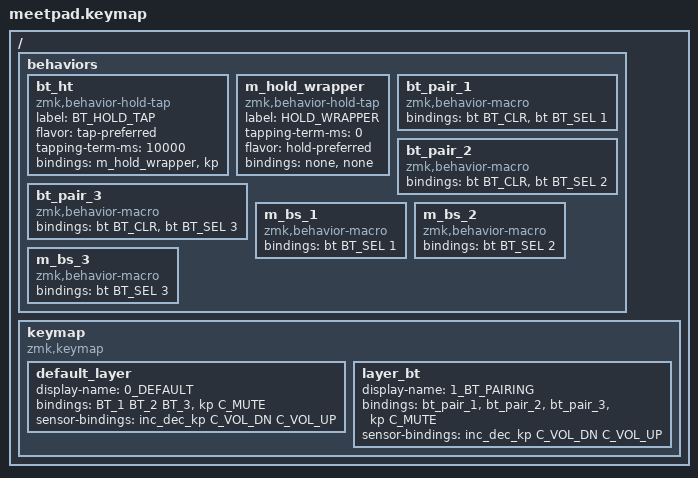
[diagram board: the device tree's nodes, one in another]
#include <behaviors.dtsi>
#include <dt-bindings/zmk/keys.h>
#include <dt-bindings/zmk/bt.h>

/ {
    behaviors {
        bt_ht: bt_ht {
            compatible = "zmk,behavior-hold-tap";
            label = "BT_HOLD_TAP";
            flavor = "tap-preferred";
            tapping-term-ms = <10000>;
            #binding-cells = <2>;
            bindings = <&m_hold_wrapper>, <&kp>;
        };

        m_hold_wrapper: m_hold_wrapper {
            compatible = "zmk,behavior-hold-tap";
            label = "HOLD_WRAPPER";
            #binding-cells = <2>;
            tapping-term-ms = <0>;
            flavor = "hold-preferred";
            bindings = <&none>, <&none>;
        };

        bt_pair_1: bt_pair_1 {
            compatible = "zmk,behavior-macro";
            #binding-cells = <0>;
            bindings = <&bt BT_CLR &bt BT_SEL 1>;
        };

        bt_pair_2: bt_pair_2 {
            compatible = "zmk,behavior-macro";
            #binding-cells = <0>;
            bindings = <&bt BT_CLR &bt BT_SEL 2>;
        };

        bt_pair_3: bt_pair_3 {
            compatible = "zmk,behavior-macro";
            #binding-cells = <0>;
            bindings = <&bt BT_CLR &bt BT_SEL 3>;
        };

        m_bs_1: m_bs_1 {
            compatible = "zmk,behavior-macro";
            #binding-cells = <0>;
            bindings = <&bt BT_SEL 1>;
        };

        m_bs_2: m_bs_2 {
            compatible = "zmk,behavior-macro";
            #binding-cells = <0>;
            bindings = <&bt BT_SEL 2>;
        };

        m_bs_3: m_bs_3 {
            compatible = "zmk,behavior-macro";
            #binding-cells = <0>;
            bindings = <&bt BT_SEL 3>;
        };
    };

    #define BT_1 &bt_ht &m_bs_1 LS(LG(M))
    #define BT_2 &bt_ht &m_bs_2 LS(LG(K))
    #define BT_3 &bt_ht &m_bs_3 LS(LG(O))

    keymap {
        compatible = "zmk,keymap";

        default_layer {
            display-name = "0_DEFAULT";
            bindings = <
                BT_1
                BT_2
                BT_3
                &kp C_MUTE
            >;
            sensor-bindings = <&inc_dec_kp C_VOL_DN C_VOL_UP>;
        };

        layer_bt {
            display-name = "1_BT_PAIRING";
            bindings = <
                &bt_pair_1
                &bt_pair_2
                &bt_pair_3
                &kp C_MUTE
            >;
            sensor-bindings = <&inc_dec_kp C_VOL_DN C_VOL_UP>;
        };
    };
};
